# STM32L4R9ZIY6P register map
File version: 1.0
Registers are 32-bit, access not given, reset 0x0 unless marked. A register's access mark holds for its fields unless they carry their own. Offsets are from the block's base; [hi:lo] are bit positions; {n}, {i} and the like mark numbered series; 'fields as' and 'values as' point back to an identical list.

## DFSDM1
Base 0x40016000
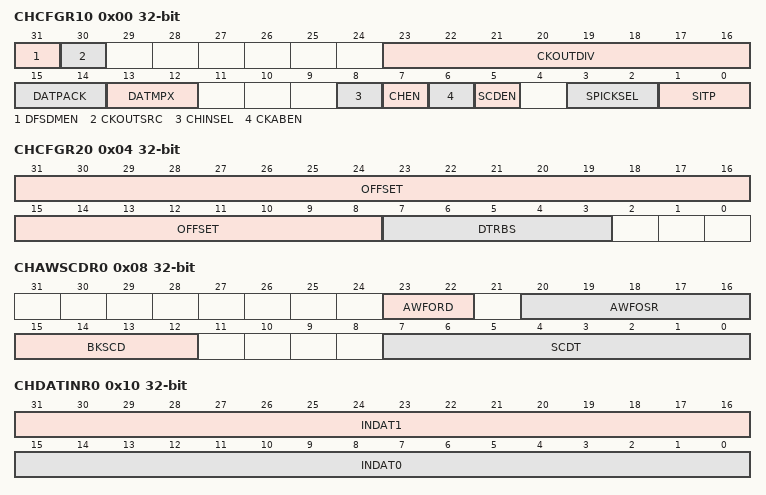
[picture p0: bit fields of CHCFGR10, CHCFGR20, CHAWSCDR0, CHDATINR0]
0x00 CHCFGR10
  [31] DFSDMEN, [30] CKOUTSRC, [23:16] CKOUTDIV, [15:14] DATPACK, [13:12] DATMPX, [8] CHINSEL, [7] CHEN, [6] CKABEN, [5] SCDEN, [3:2] SPICKSEL, [1:0] SITP
0x04 CHCFGR20
  [31:8] OFFSET, [7:3] DTRBS
0x08 CHAWSCDR0
  [23:22] AWFORD, [20:16] AWFOSR, [15:12] BKSCD, [7:0] SCDT
0x0C CHWDATAR0
0x10 CHDATINR0
  [31:16] INDAT1, [15:0] INDAT0
0x14 CHDLYR0
  [5:0] PLSSKP
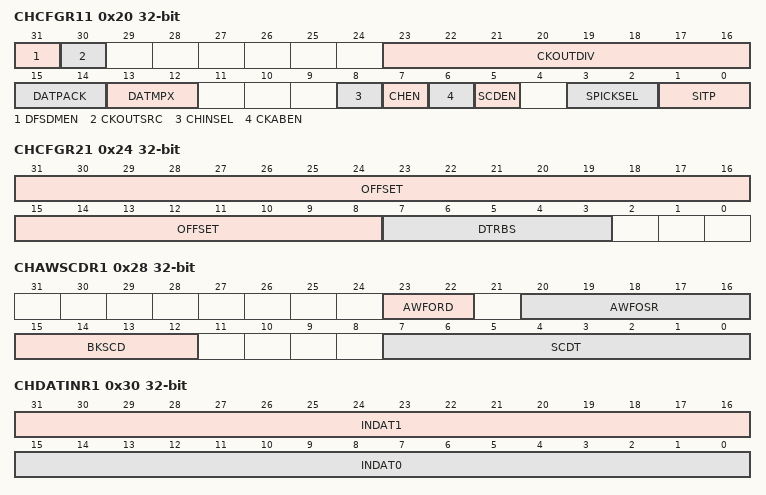
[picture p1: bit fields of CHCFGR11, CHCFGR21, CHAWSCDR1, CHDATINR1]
0x20 CHCFGR11
  fields as CHCFGR10
0x24 CHCFGR21
  [31:8] OFFSET, [7:3] DTRBS
0x28 CHAWSCDR1
  [23:22] AWFORD, [20:16] AWFOSR, [15:12] BKSCD, [7:0] SCDT
0x2C CHWDATAR1
0x30 CHDATINR1
  [31:16] INDAT1, [15:0] INDAT0
0x34 CHDLYR1
  [5:0] PLSSKP
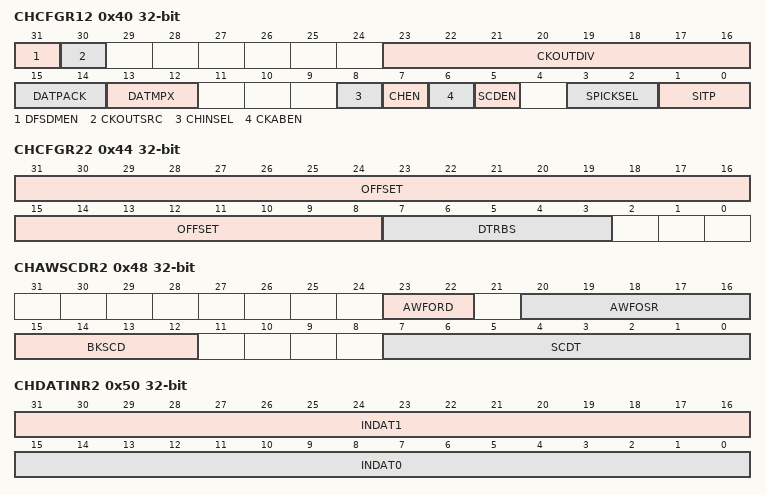
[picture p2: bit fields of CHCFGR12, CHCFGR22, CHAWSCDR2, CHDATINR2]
0x40 CHCFGR12
  fields as CHCFGR10
0x44 CHCFGR22
  [31:8] OFFSET, [7:3] DTRBS
0x48 CHAWSCDR2
  [23:22] AWFORD, [20:16] AWFOSR, [15:12] BKSCD, [7:0] SCDT
0x4C CHWDATAR2
0x50 CHDATINR2
  [31:16] INDAT1, [15:0] INDAT0
0x54 CHDLYR2
  [5:0] PLSSKP
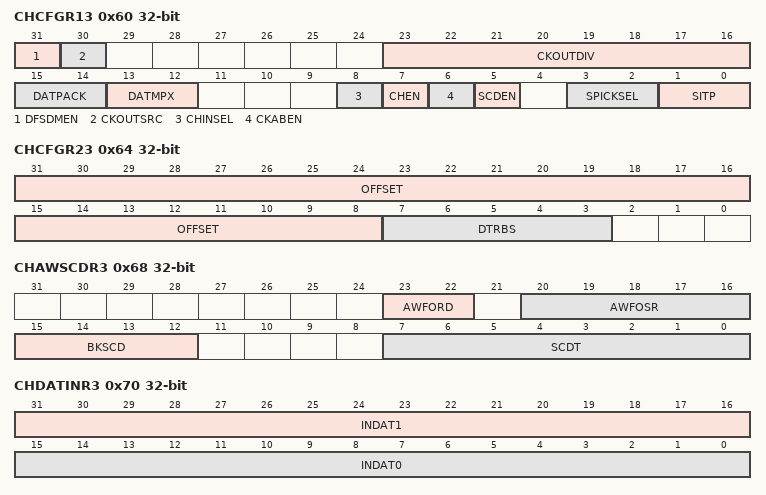
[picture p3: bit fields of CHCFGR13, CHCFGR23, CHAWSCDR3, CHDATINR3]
0x60 CHCFGR13
  fields as CHCFGR10
0x64 CHCFGR23
  [31:8] OFFSET, [7:3] DTRBS
0x68 CHAWSCDR3
  [23:22] AWFORD, [20:16] AWFOSR, [15:12] BKSCD, [7:0] SCDT
0x6C CHWDATAR3
0x70 CHDATINR3
  [31:16] INDAT1, [15:0] INDAT0
0x74 CHDLYR3
  [5:0] PLSSKP
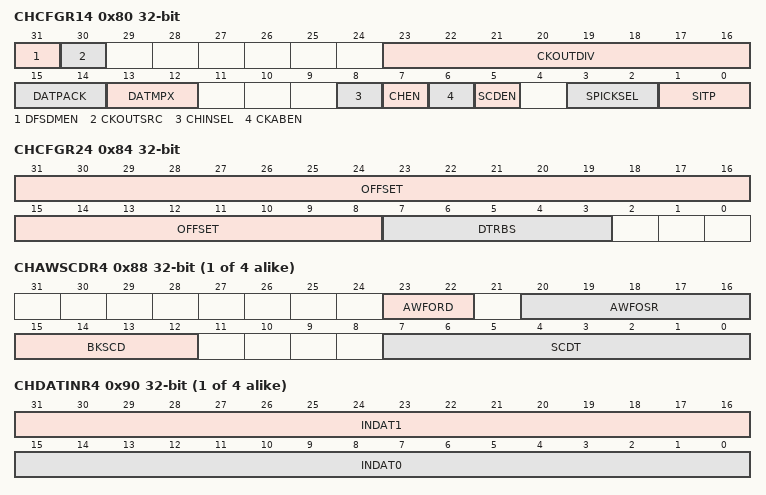
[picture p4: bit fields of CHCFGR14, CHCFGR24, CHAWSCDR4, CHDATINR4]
0x80 CHCFGR14
  fields as CHCFGR10
0x84 CHCFGR24
  [31:8] OFFSET, [7:3] DTRBS
{0x8+0x20*i} CHAWSCDR{i} (i=4..7)
  [23:22] AWFORD, [20:16] AWFOSR, [15:12] BKSCD, [7:0] SCDT
{0xC+0x20*i} CHWDATAR{i} (i=4..7)
{0x10+0x20*i} CHDATINR{i} (i=4..7)
  [31:16] INDAT1, [15:0] INDAT0
{0x14+0x20*i} CHDLYR{i} (i=4..7)
  [5:0] PLSSKP
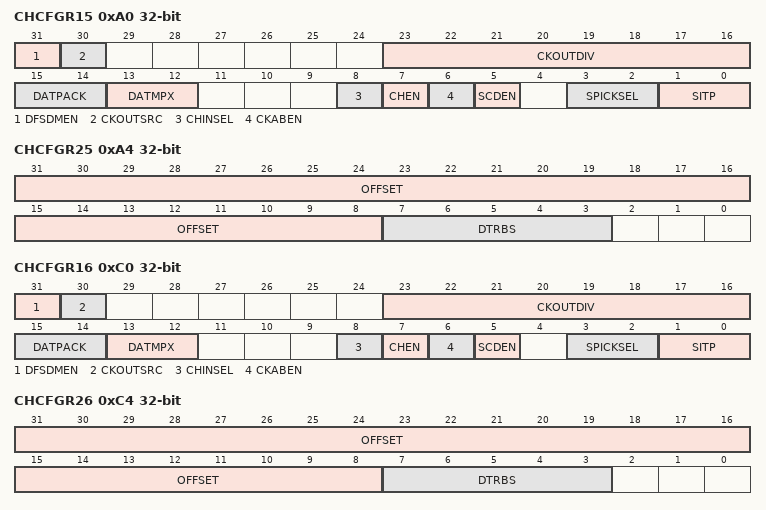
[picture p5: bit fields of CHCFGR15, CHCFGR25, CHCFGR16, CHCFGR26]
0xA0 CHCFGR15
  fields as CHCFGR10
0xA4 CHCFGR25
  [31:8] OFFSET, [7:3] DTRBS
0xC0 CHCFGR16
  fields as CHCFGR10
0xC4 CHCFGR26
  [31:8] OFFSET, [7:3] DTRBS
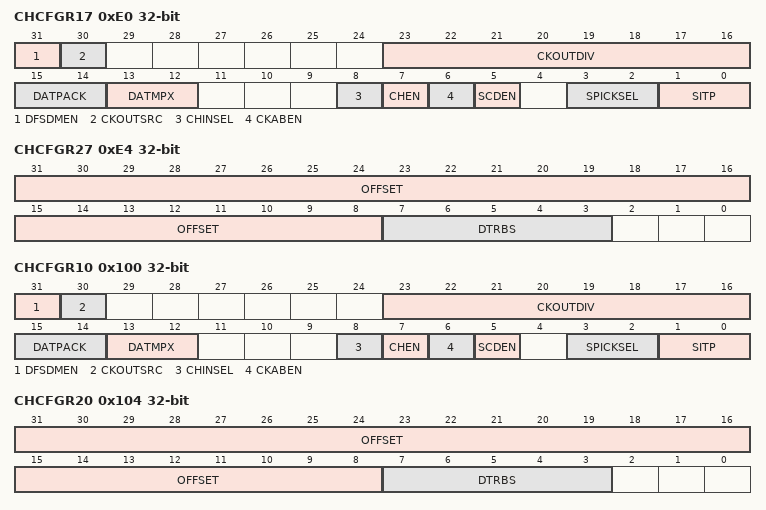
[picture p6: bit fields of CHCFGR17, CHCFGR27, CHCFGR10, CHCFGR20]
0xE0 CHCFGR17
  fields as CHCFGR10
0xE4 CHCFGR27
  [31:8] OFFSET, [7:3] DTRBS
0x100 CHCFGR10
  fields as CHCFGR10
0x104 CHCFGR20
  [31:8] OFFSET, [7:3] DTRBS
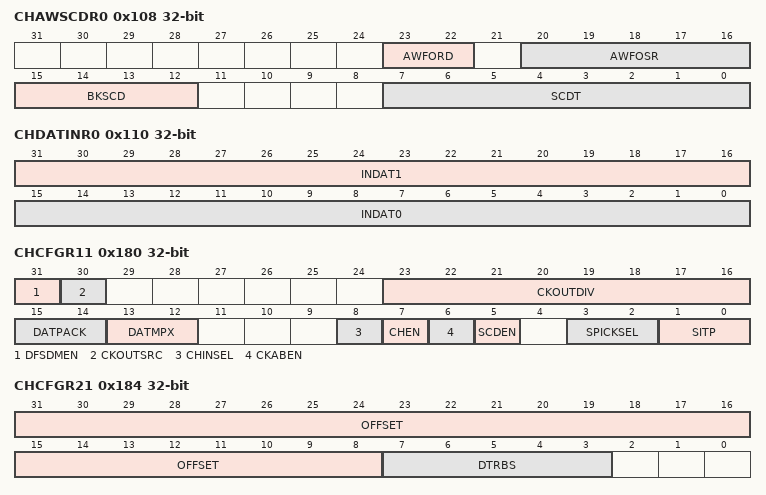
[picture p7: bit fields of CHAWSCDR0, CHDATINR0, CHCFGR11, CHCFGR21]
0x108 CHAWSCDR0
  [23:22] AWFORD, [20:16] AWFOSR, [15:12] BKSCD, [7:0] SCDT
0x10C CHWDATAR0
0x110 CHDATINR0
  [31:16] INDAT1, [15:0] INDAT0
0x114 CHDLYR0
  [5:0] PLSSKP
0x180 CHCFGR11
  fields as CHCFGR10
0x184 CHCFGR21
  [31:8] OFFSET, [7:3] DTRBS
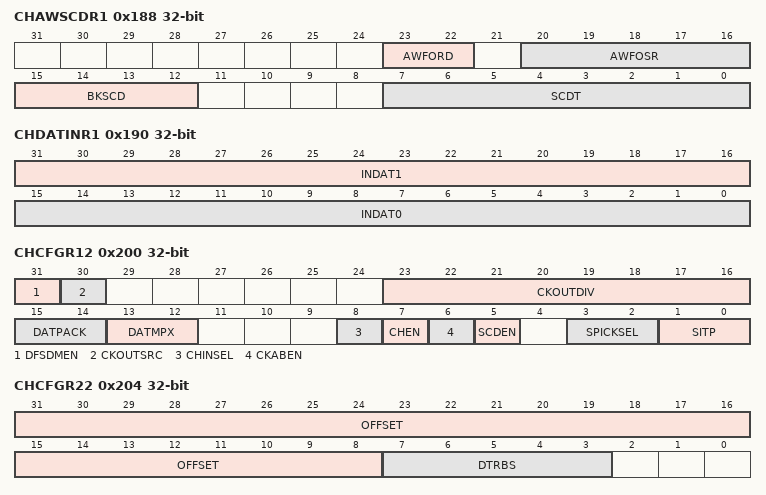
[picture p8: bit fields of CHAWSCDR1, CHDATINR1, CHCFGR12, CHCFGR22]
0x188 CHAWSCDR1
  [23:22] AWFORD, [20:16] AWFOSR, [15:12] BKSCD, [7:0] SCDT
0x18C CHWDATAR1
0x190 CHDATINR1
  [31:16] INDAT1, [15:0] INDAT0
0x194 CHDLYR1
  [5:0] PLSSKP
0x200 CHCFGR12
  fields as CHCFGR10
0x204 CHCFGR22
  [31:8] OFFSET, [7:3] DTRBS
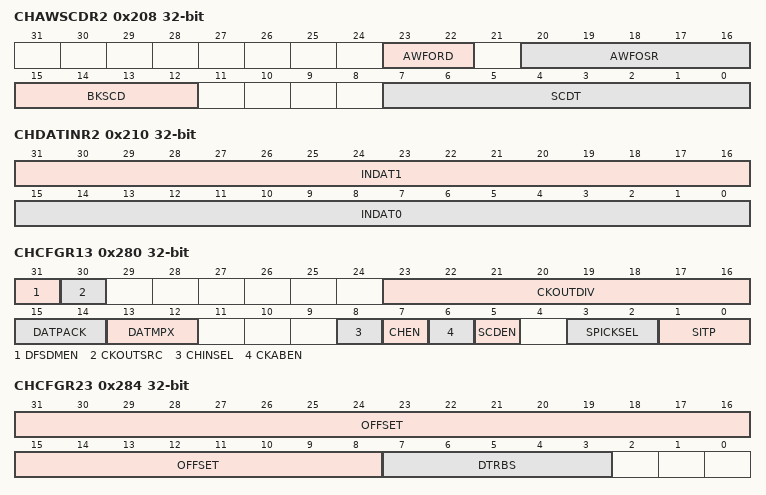
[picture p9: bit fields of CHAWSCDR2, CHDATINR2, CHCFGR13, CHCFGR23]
0x208 CHAWSCDR2
  [23:22] AWFORD, [20:16] AWFOSR, [15:12] BKSCD, [7:0] SCDT
0x20C CHWDATAR2
0x210 CHDATINR2
  [31:16] INDAT1, [15:0] INDAT0
0x214 CHDLYR2
  [5:0] PLSSKP
0x280 CHCFGR13
  fields as CHCFGR10
0x284 CHCFGR23
  [31:8] OFFSET, [7:3] DTRBS
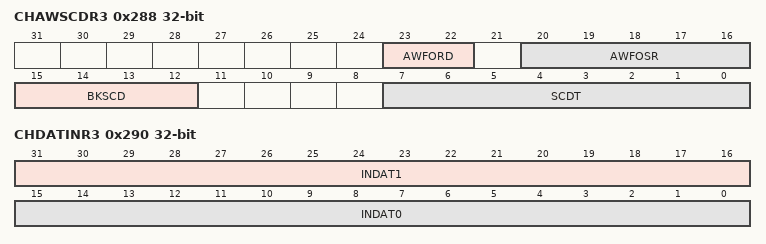
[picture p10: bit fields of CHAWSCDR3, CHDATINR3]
0x288 CHAWSCDR3
  [23:22] AWFORD, [20:16] AWFOSR, [15:12] BKSCD, [7:0] SCDT
0x28C CHWDATAR3
0x290 CHDATINR3
  [31:16] INDAT1, [15:0] INDAT0
0x294 CHDLYR3
  [5:0] PLSSKP

## LTDC
Base 0x40016800
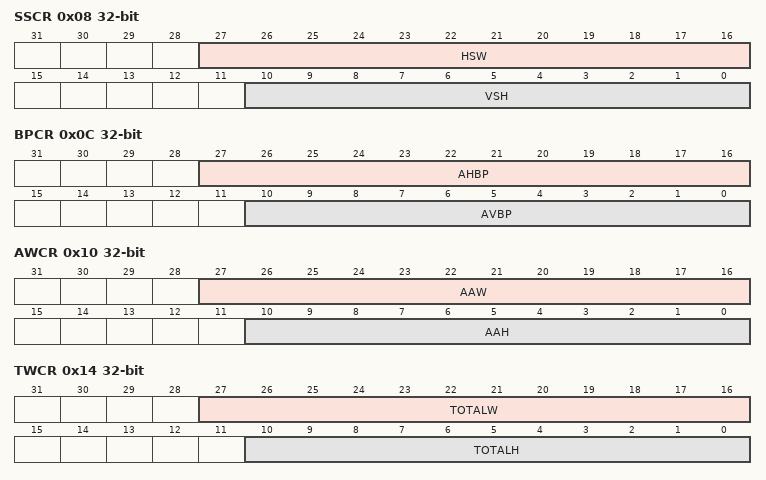
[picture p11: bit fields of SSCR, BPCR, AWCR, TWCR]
0x08 SSCR
  [27:16] HSW, [10:0] VSH
0x0C BPCR
  [27:16] AHBP, [10:0] AVBP
0x10 AWCR
  [27:16] AAW, [10:0] AAH
0x14 TWCR
  [27:16] TOTALW, [10:0] TOTALH
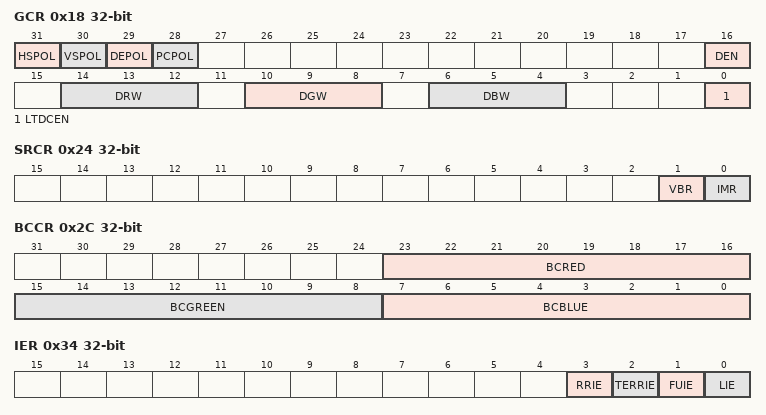
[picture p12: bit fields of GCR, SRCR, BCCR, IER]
0x18 GCR
  [31] HSPOL, [30] VSPOL, [29] DEPOL, [28] PCPOL, [16] DEN, [14:12] DRW, [10:8] DGW, [6:4] DBW, [0] LTDCEN
0x24 SRCR
  [1] VBR, [0] IMR
0x2C BCCR
  [23:16] BCRED, [15:8] BCGREEN, [7:0] BCBLUE
0x34 IER
  [3] RRIE, [2] TERRIE, [1] FUIE, [0] LIE
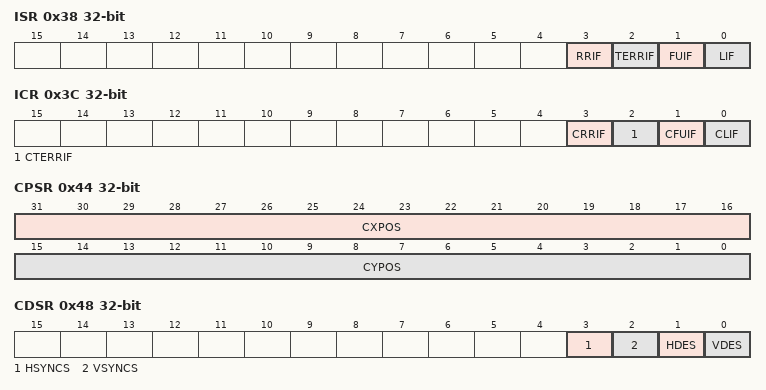
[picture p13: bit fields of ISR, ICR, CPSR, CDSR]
0x38 ISR
  [3] RRIF, [2] TERRIF, [1] FUIF, [0] LIF
0x3C ICR
  [3] CRRIF, [2] CTERRIF, [1] CFUIF, [0] CLIF
0x40 LIPCR
  [10:0] LIPOS
0x44 CPSR
  [31:16] CXPOS, [15:0] CYPOS
0x48 CDSR
  [3] HSYNCS, [2] VSYNCS, [1] HDES, [0] VDES
0x84 CR1
0x88 WHPCR1
0x8C WVPCR1
0x90 CKCR1
0x94 PFCR1
0x98 CACR1
0x9C DCCR1
0xA0 BFCR1
0xAC CFBAR1
0xB0 CFBLR1
0xB4 CFBLNR1
0xC4 CLUTWR1
0x104 CR2
0x108 WHPCR2
0x10C WVPCR2
0x110 CKCR2
0x114 PFCR2
0x118 CACR2
0x11C DCCR2
0x120 BFCR2
0x12C CFBAR2
0x130 CFBLR2
0x134 CFBLNR2
0x144 CLUTWR2

## DMA1
Base 0x40020000
Same registers: DMA2 0x40020400
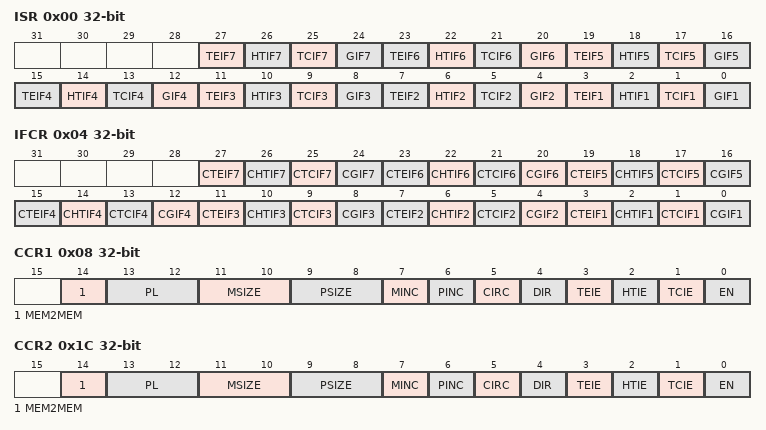
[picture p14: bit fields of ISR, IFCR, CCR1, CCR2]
0x00 ISR
  [4n-1] TEIF{n} (n=1..7), [4n-2] HTIF{n} (n=1..7), [4n-3] TCIF{n} (n=1..7), [4n-4] GIF{n} (n=1..7)
0x04 IFCR
  [4n-1] CTEIF{n} (n=1..7), [4n-2] CHTIF{n} (n=1..7), [4n-3] CTCIF{n} (n=1..7), [4n-4] CGIF{n} (n=1..7)
0x08 CCR1
  [14] MEM2MEM, [13:12] PL, [11:10] MSIZE, [9:8] PSIZE, [7] MINC, [6] PINC, [5] CIRC, [4] DIR, [3] TEIE, [2] HTIE, [1] TCIE, [0] EN
0x0C CNDTR1
  [15:0] NDT
0x10 CPAR1
  [31:0] PA
{0x0+0x14*i} CMAR{i} (i=1..7)
  [31:0] MA
0x1C CCR2
  fields as CCR1
0x20 CNDTR2
  [15:0] NDT
0x24 CPAR2
  [31:0] PA
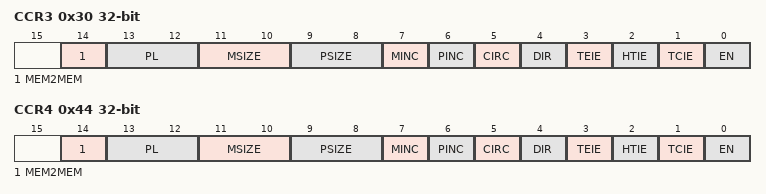
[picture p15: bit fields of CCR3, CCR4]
0x30 CCR3
  fields as CCR1
0x34 CNDTR3
  [15:0] NDT
0x38 CPAR3
  [31:0] PA
0x44 CCR4
  fields as CCR1
0x48 CNDTR4
  [15:0] NDT
0x4C CPAR4
  [31:0] PA
0x58 CCR5
  fields as CCR1
0x5C CNDTR5
  [15:0] NDT
0x60 CPAR5
  [31:0] PA
0x6C CCR6
  fields as CCR1
0x70 CNDTR6
  [15:0] NDT
0x74 CPAR6
  [31:0] PA
0x80 CCR7
  fields as CCR1
0x84 CNDTR7
  [15:0] NDT
0x88 CPAR7
  [31:0] PA
